VERSION "TOOL OF INVENTEC AND KOSTAL"

NS_ :

BS_:

BU_: NM_Tester

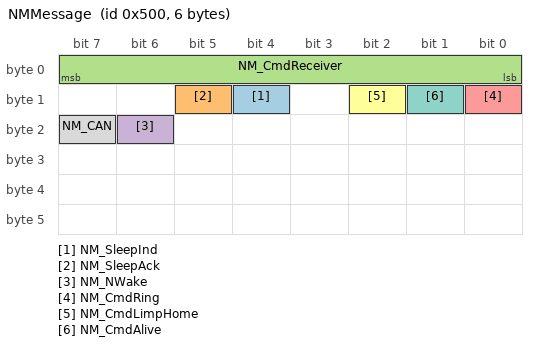
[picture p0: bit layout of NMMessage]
BO_ 1280 NMMessage: 6 NM_Tester
 SG_ NM_SleepInd : 12|1@1+ (1,0) [0|1] ""  Vector__XXX
 SG_ NM_SleepAck : 13|1@1+ (1,0) [0|1] ""  Vector__XXX
 SG_ NM_CmdReceiver : 0|8@1+ (1,0) [0|255] ""  Vector__XXX
 SG_ NM_NWake : 22|1@1+ (1,0) [0|1] ""  Vector__XXX
 SG_ NM_CmdRing : 8|1@1+ (1,0) [0|1] ""  Vector__XXX
 SG_ NM_CmdLimpHome : 10|1@1+ (1,0) [0|1] ""  Vector__XXX
 SG_ NM_CmdAlive : 9|1@1+ (1,0) [0|1] ""  Vector__XXX
 SG_ NM_CAN : 23|1@1+ (1,0) [0|1] ""  Vector__XXX
